# DA1470x register map
Vendor: Dialog; Series: DA1470x; File version: 1.2
CPU: CM33 r0p2, little endian, MPU, FPU, DSP, VTOR, 4 interrupt priority bits
Registers are 32-bit, read-write, reset 0x0 unless marked. A register's access mark holds for its fields unless they carry their own. Offsets are from the block's base; [hi:lo] are bit positions.

## CACHE — CACHE registers
Base 0x100C0000
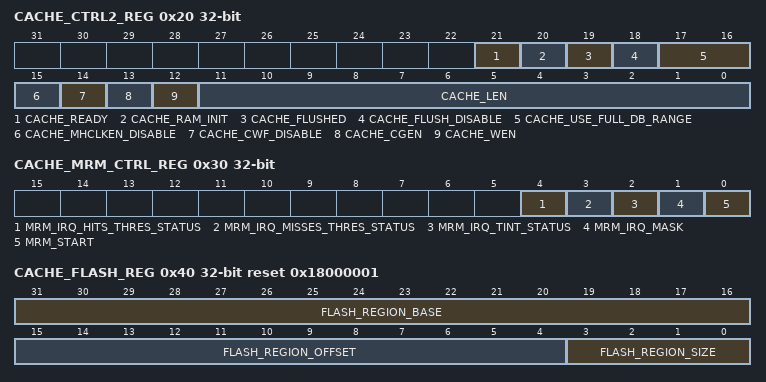
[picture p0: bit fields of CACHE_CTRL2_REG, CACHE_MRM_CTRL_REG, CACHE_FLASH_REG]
0x20 CACHE_CTRL2_REG — Cache control register 2 (only Word (32-bits) access supported).
  [21] CACHE_READY ro — Cache Controller RO status bit. 0: Default. 1: Set to '1' when CACHE_CTRL is enabled, initialized and immediately ready for a cacheable access to service.
  [20] CACHE_RAM_INIT ro — Cache Controller RO status bit. 0: Default. 1: Set to '1' when SRAM is being initialized (i.e. being flushed). Note: The flushing of the cache memory takes 256 HCLK cycles.
  [19] CACHE_FLUSHED — 0: Cache is not flushed yet. 1: Cache is flushed. Note 1: Setting and clearing of this (status) bit field is automatically done by the hardware. It is set on the falling edge and cleared on the rising edge of the (Cache Controller) CACHE_RAM_INIT signal. Note 2: When the Cache is flushed by disabling and enabling the Cache Controller with a SYS_CTRL_REG[CACHERAM_MUX] sequence of 1 -> 0 -> 1, the CACHE_FLUSHED bit can also be cleared first by the software (if needed) with writing a CACHE_CTRL2_REG(CACHE_FLUSHED) sequence of 1 -> 0. This is needed when the software uses the CACHE_FLUSHED bit as a status bit to wait for (e.g. in a while-loop).
  [18] CACHE_FLUSH_DISABLE — 0: Default. 1: Flushing of the Cache memory is disabled when SYS_CTRL_REG[CACHERAM_MUX] is switched from '1' to '0'. Note: Setting this bit to '1' is only allowed for debugging purposes.
  [17:16] CACHE_USE_FULL_DB_RANGE — 00: CACHERAM (mirrored) read/write and NO use of the full 184 bits databus (for executing program code or extension of the SysRAM with the Cache RAM). In this mode 8 bits, 16 bits and 32 bits write access is supported. 01: CACHERAM (mirrored) read and use of the full 184 bits databus of 'SRAM_1_0' (for testing and debugging purposes). In this mode only 32 bits write access is supported. 10: CACHERAM (mirrored) read and use of the full 184 bits databus of 'SRAM_3_2' (for testing and debugging purposes). In this mode only 32 bits write access is supported. 11: Reserved. Note 1: SYS_CTRL_REG[CACHERAM_MUX] must be set to '0' before accessing the memory mapped (mirrored) Cache Data and TAG memory. Note 2: For all 3 settings, max. 8 KByte is available from the memory map.
  [15] CACHE_MHCLKEN_DISABLE — 0: Default. 1: The "m_HCLK_EN" input is ignored and the controller avoids inserting m_HTRANS=BUSY because of wait states. Note: This bit is only relevant for executing from QSPI Flash (when set to '1' it will improve performance). This bit should be kept on '0' for executing from eFlash.
  [14] CACHE_CWF_DISABLE — 0: Default. 1: The cache line refill is performed with INCR type burst and "Critical Word First" is disabled. Note: This bit is only relevant for executing from QSPI Flash (when set to '1' it will improve performance).This bit should be kept on '0' for executing from eFlash.
  [13] CACHE_CGEN — 0: Cache controller clock gating is not enabled. 1: Cache controller clock gating is enabled (enabling power saving).
  [12] CACHE_WEN — 0: Cache Data and TAG memory read only. 1: Cache Data and TAG memory read/write. The Data and TAG memory are only updated by the cache controller. There is no HW protection to prevent unauthorized access by the ARM. Note 1: When accessing the memory mapped Cache Data and TAG memory (which is only allowed for debugging purposes) only 32 bits access is supported. Note 2: SYS_CTRL_REG[CACHERAM_MUX] must be set to '0' before accessing the memory mapped Cache Data and TAG memory. See also the CACHE_CTRL2_REG[CACHE_USE_FULL_DB_RANGE] description.
  [11:0] CACHE_LEN — Length of OQSPI FLASH cacheable memory. N*64 KBytes. N = 0 to 2048, incl. 2048 (max. of 128 Mbytes). Setting CACHE_LEN=0 disables the caching. Note 1: The max. relevant CACHE_LEN setting depends on the chosen Flash region (program) size. Note 2: The first block (CACHE_LEN=1) includes the memory space specified by CACHE_FLASH_REG[FLASH_REGION_OFFSET].
0x28 CACHE_MRM_HITS_REG (reset mask 0x7FFFFFFF) — Cache MRM (Miss Rate Monitor) HITS register (only Word (32-bits) access supported).
  [31:0] MRM_HITS — Contains the amount of cache hits.
0x2C CACHE_MRM_MISSES_REG (reset mask 0x7FFFFFFF) — Cache MRM (Miss Rate Monitor) MISSES register (only Word (32-bits) access supported).
  [31:0] MRM_MISSES — Contains the amount of cache misses.
0x30 CACHE_MRM_CTRL_REG — Cache MRM (Miss Rate Monitor) CONTROL register (only Word (32-bits) access supported).
  [4] MRM_IRQ_HITS_THRES_STATUS — 0: No interrupt is generated. 1: Interrupt (pulse-sensitive) is generated because the number of cache hits reached the programmed threshold (threshold != 0).
  [3] MRM_IRQ_MISSES_THRES_STATUS — 0: No interrupt is generated. 1: Interrupt (pulse-sensitive) is generated because the number of cache misses reached the programmed threshold (threshold != 0).
  [2] MRM_IRQ_TINT_STATUS — 0: No interrupt is generated. 1: Interrupt (pulse-sensitive) is generated because the time interval counter reached the end (time interval != 0).
  [1] MRM_IRQ_MASK — 0: Disables interrupt generation. 1: Enables interrupt generation. Note: The Cache MRM generates a pulse-sensitive interrupt towards the ARM processor,
  [0] MRM_START — 0: Freeze the "misses/hits" counters and reset the time interval counter to the programmed value in CACHE_MRM_TINT_REG. 1: Enables the counters. Note: In case CACHE_MRM_CTRL_REG[MRM_START] is set to '1' and CACHE_MRM_TINT_REG (!=0) is used for the MRM interrupt generation, the time interval counter counts down (on a fixed reference clock of 32 MHz) until it's '0'. At that time CACHE_MRM_CTRL_REG[MRM_START] will be reset automatically to '0' by the MRM hardware and the MRM interrupt will be generated.
0x34 CACHE_MRM_TINT_REG — Cache MRM (Miss Rate Monitor) TIME INTERVAL register (only Word (32-bits) access supported).
  [18:0] MRM_TINT — Defines the time interval for the monitoring in 32 MHz clock cycles. See also the description of CACHE_MRM_CTRL_REG[MRM_IRQ_TINT_STATUS]. Note: When MRM_TINT=0 (unrealistic value), no interrupt will be generated.
0x38 CACHE_MRM_MISSES_THRES_REG (reset mask 0x7FFFFFFF) — Cache MRM (Miss Rate Monitor) THRESHOLD register (only Word (32-bits) access supported).
  [31:0] MRM_MISSES_THRES — Defines the misses threshold to trigger the interrupt generation. See also the description of CACHE_MRM_CTRL_REG[MRM_IRQ_MISSES_THRES_STATUS]. Note: When MRM_MISSES_THRES=0 (unrealistic value), no interrupt will be generated.
0x3C CACHE_MRM_HITS_THRES_REG (reset mask 0x7FFFFFFF) — Cache MRM (Miss Rate Monitor) HITS THRESHOLD register (only Word (32-bits) access supported).
  [31:0] MRM_HITS_THRES — Defines the hits threshold to trigger the interrupt generation. See also the description of CACHE_MRM_CTRL_REG[MRM_IRQ_HITS_THRES_STATUS]. Note: When MRM_HITS_THRES=0 (unrealistic value), no interrupt will be generated.
0x40 CACHE_FLASH_REG reset 0x18000001 (reset mask 0x7FFFFFFF) — Cache QSPI Flash program size and base address register (only Word (32-bits) access supported).
  [31:16] FLASH_REGION_BASE — These bits corresponds with the Flash region base address bits [31:16]. Default value is '0x1800'. The Flash region base address bits [31:27] are fixed to '0b00011', supporting the range of 0x1800-0x1FFF'. These register bits are retained. Note 1: The updated value takes effect only after a software reset. Note 2 The Flash region base address setting depends on the chosen Flash region size.
  [15:4] FLASH_REGION_OFFSET — Flash region offset address (in words). This value is added to the Flash (CPU) address bits [13:2]. These register bits are retained. Note 1: The updated value takes effect only after a software reset.
  [3:0] FLASH_REGION_SIZE — Flash region size. Default value is '1' (0.5 MBytes). 0 = 0.25 MBytes, 1 = 0.5 MBytes, 2 = 1 MBytes, 3 = 2 MBytes, 4 = 4 MBytes, 5 = 8 MBytes, 6 = 16 MBytes, 7 = 32 MBytes, 8 = 64 MBytes, 9 = 128 MBytes. These register bits are retained. Note 1: The updated value takes effect only after a software reset. Note 2: See for the max. region (program) size the memory map.
0x48 CACHE_MRM_HITS1WS_REG (reset mask 0x7FFFFFFF) — Cache MRM (Miss Rate Monitor) HITS with 1 Wait State register (only Word (32-bits) access supported).
  [31:0] MRM_HITS1WS — Contains the amount of cache hits.
0x50 SWD_RESET_REG — SWD HW reset control register (only Word (32-bits) access supported).
  [0] SWD_HW_RESET_REQ wo — 0: default. 1: HW reset request (from the debugger tool). The register is automatically reset with a HW_RESET. This bit can only be accessed by the debugger software and not by the application.
